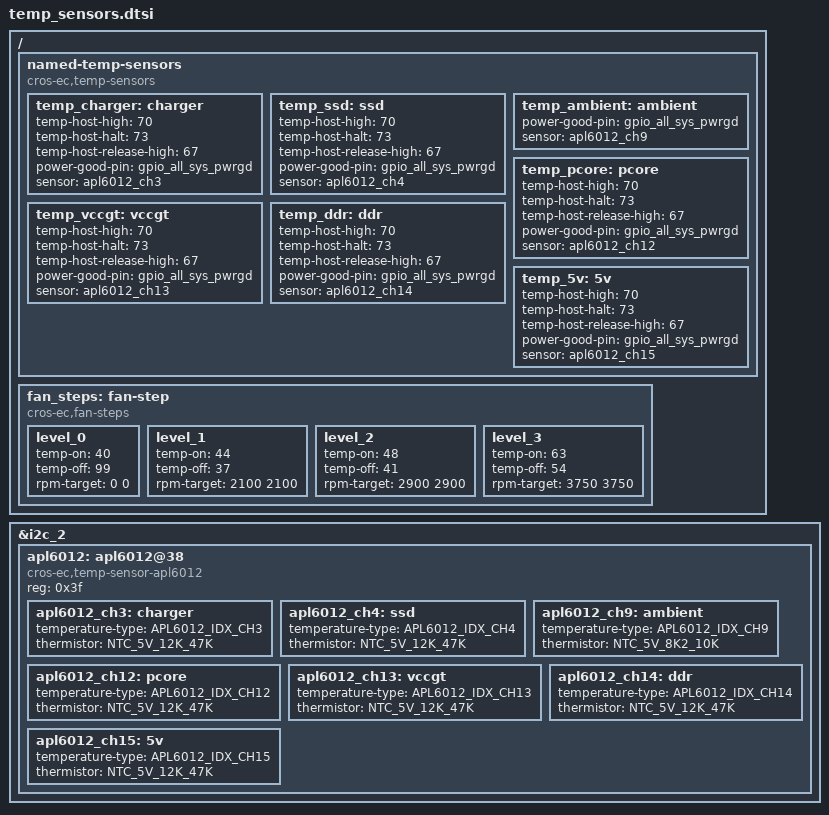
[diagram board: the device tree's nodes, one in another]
/* Copyright 2026 The ChromiumOS Authors
 * Use of this source code is governed by a BSD-style license that can be
 * found in the LICENSE file.
 */
#include <cros/thermistor/thermistor.dtsi>

/ {
	named-temp-sensors {
		compatible = "cros-ec,temp-sensors";

		temp_charger: charger {
			temp-host-high = <70>;
			temp-host-halt = <73>;
			temp-host-release-high = <67>;
			power-good-pin = <&gpio_all_sys_pwrgd>;
			sensor = <&apl6012_ch3>;
		};
		temp_ssd: ssd {
			temp-host-high = <70>;
			temp-host-halt = <73>;
			temp-host-release-high = <67>;
			power-good-pin = <&gpio_all_sys_pwrgd>;
			sensor = <&apl6012_ch4>;
		};
		temp_ambient: ambient {
			// temp-host-high = <70>;
			// temp-host-halt = <73>;
			// temp-host-release-high = <67>;
			power-good-pin = <&gpio_all_sys_pwrgd>;
			sensor = <&apl6012_ch9>;
		};
		temp_pcore: pcore {
			temp-host-high = <70>;
			temp-host-halt = <73>;
			temp-host-release-high = <67>;
			power-good-pin = <&gpio_all_sys_pwrgd>;
			sensor = <&apl6012_ch12>;
		};
		temp_vccgt: vccgt {
			temp-host-high = <70>;
			temp-host-halt = <73>;
			temp-host-release-high = <67>;
			power-good-pin = <&gpio_all_sys_pwrgd>;
			sensor = <&apl6012_ch13>;
		};
		temp_ddr: ddr {
			temp-host-high = <70>;
			temp-host-halt = <73>;
			temp-host-release-high = <67>;
			power-good-pin = <&gpio_all_sys_pwrgd>;
			sensor = <&apl6012_ch14>;
		};
		temp_5v: 5v {
			temp-host-high = <70>;
			temp-host-halt = <73>;
			temp-host-release-high = <67>;
			power-good-pin = <&gpio_all_sys_pwrgd>;
			sensor = <&apl6012_ch15>;
		};
	};

	fan_steps: fan-step {
		compatible = "cros-ec,fan-steps";

		level_0 {
			temp-on = <40>;
			temp-off = <99>;
			rpm-target = <0 0>;
		};
		level_1 {
			temp-on = <44>;
			temp-off = <37>;
			rpm-target = <2100 2100>;
		};
		level_2 {
			temp-on = <48>;
			temp-off = <41>;
			rpm-target = <2900 2900>;
		};
		level_3 {
			temp-on = <63>;
			temp-off = <54>;
			rpm-target = <3750 3750>;
		};
	};
};

&i2c_2 {
	apl6012: apl6012@38 {
		compatible = "cros-ec,temp-sensor-apl6012";
		reg = <0x3f>;

		apl6012_ch3: charger {
			temperature-type = "APL6012_IDX_CH3";
			thermistor = <&NTC_5V_12K_47K>;
		};
		apl6012_ch4: ssd {
			temperature-type = "APL6012_IDX_CH4";
			thermistor = <&NTC_5V_12K_47K>;
		};
		apl6012_ch9: ambient {
			temperature-type = "APL6012_IDX_CH9";
			thermistor = <&NTC_5V_8K2_10K>;
		};
		apl6012_ch12: pcore {
			temperature-type = "APL6012_IDX_CH12";
			thermistor = <&NTC_5V_12K_47K>;
		};
		apl6012_ch13: vccgt {
			temperature-type = "APL6012_IDX_CH13";
			thermistor = <&NTC_5V_12K_47K>;
		};
		apl6012_ch14: ddr {
			temperature-type = "APL6012_IDX_CH14";
			thermistor = <&NTC_5V_12K_47K>;
		};
		apl6012_ch15: 5v {
			temperature-type = "APL6012_IDX_CH15";
			thermistor = <&NTC_5V_12K_47K>;
		};
	};
};
